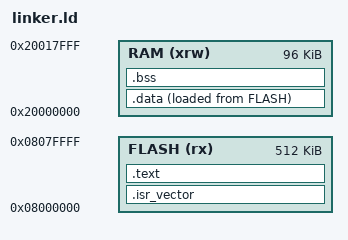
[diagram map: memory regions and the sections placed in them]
MEMORY
{
  RAM  (xrw) : ORIGIN = 0x20000000, LENGTH = 96K
  FLASH (rx) : ORIGIN = 0x08000000, LENGTH = 512K
}

_estack = ORIGIN(RAM) + LENGTH(RAM);

SECTIONS
{
  .isr_vector :
  {
    . = ALIGN(4);
    KEEP(*(.isr_vector))
    . = ALIGN(4);
  } >FLASH

  .text :
  {
    . = ALIGN(4);
    *(.text)
    *(.text*)
    *(.rodata)
    *(.rodata.*)
    . = ALIGN(4);
  } >FLASH

  _sidata = LOADADDR(.data);

  .data :
  {
    . = ALIGN(4);
    _sdata = .;
    *(.data)
    *(.data*)
    . = ALIGN(4);
    _edata = .;
  } >RAM AT> FLASH

  .bss (NOLOAD) :
  {
    . = ALIGN(4);
    _sbss = .;
    *(.bss)
    *(.bss*)
    . = ALIGN(4);
    _ebss = .;
  } >RAM
}
